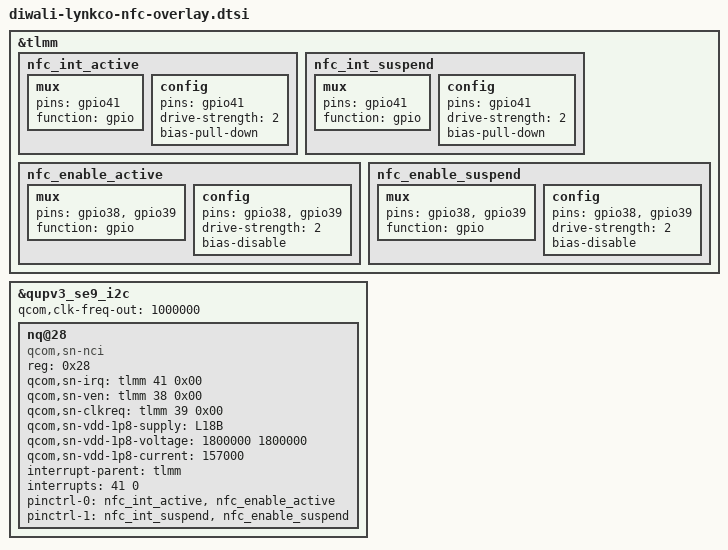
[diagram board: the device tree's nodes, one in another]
&tlmm {
	nfc_int_active: nfc_int_active {
	/* active state */
		mux {
			/* NFC Read Interrupt */
			pins = "gpio41";
			function = "gpio";
		};

		config {
			pins = "gpio41";
			drive-strength = <2>;
			bias-pull-down;
		};
	};

	nfc_int_suspend: nfc_int_suspend {
	/* sleep state */
		mux {
			/* NFC Read Interrupt */
			pins = "gpio41";
			function = "gpio";
		};

		config {
			pins = "gpio41";
			drive-strength = <2>;
			bias-pull-down;
		};
	};

	nfc_enable_active: nfc_enable_active {
		mux {
			/* Enable, Firmware and Clock request gpios */
			pins = "gpio38", "gpio39";
			function = "gpio";
		};

		config {
			pins = "gpio38", "gpio39";
			drive-strength = <2>;
			bias-disable;
		};
	};

	nfc_enable_suspend: nfc_enable_suspend {
		mux {
			pins = "gpio38", "gpio39";
			function = "gpio";
		};

		config {
			pins = "gpio38", "gpio39";
			drive-strength = <2>;
			bias-disable;
		};
	};
};

&qupv3_se9_i2c {
	status = "ok";
	qcom,clk-freq-out = <1000000>;
	#address-cells = <1>;
	#size-cells = <0>;
	nq@28 {
		compatible = "qcom,sn-nci";
		reg = <0x28>;
		qcom,sn-irq = <&tlmm 41 0x00>;
		qcom,sn-ven = <&tlmm 38 0x00>;
		qcom,sn-clkreq = <&tlmm 39 0x00>;
		qcom,sn-vdd-1p8-supply = <&L18B>;
		qcom,sn-vdd-1p8-voltage = <1800000 1800000>;
		qcom,sn-vdd-1p8-current = <157000>;
		interrupt-parent = <&tlmm>;
		interrupts = <41 0>;
		interrupt-names = "nfc_irq";
		pinctrl-names = "nfc_active", "nfc_suspend";
		pinctrl-0 = <&nfc_int_active &nfc_enable_active>;
		pinctrl-1 = <&nfc_int_suspend &nfc_enable_suspend>;
	};
};

